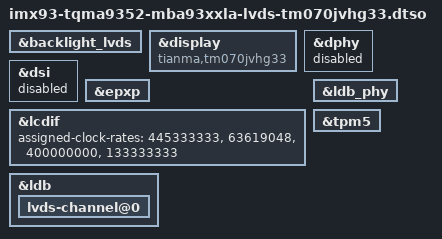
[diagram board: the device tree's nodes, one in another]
// SPDX-License-Identifier: (GPL-2.0-or-later OR MIT)
/*
 * Copyright (c) 2023-2024 TQ-Systems GmbH <linux@ew.tq-group.com>,
 * D-82229 Seefeld, Germany.
 * Author: Markus Niebel
 */

/dts-v1/;
/plugin/;

&backlight_lvds {
	status = "okay";
};

&display {
	compatible = "tianma,tm070jvhg33";
	status = "okay";
};

&dphy {
	status = "disabled";
};

&dsi {
	status = "disabled";
};

&epxp {
	status = "okay";
};

&lcdif {
	/* PLL -> pix_clk * 7 (LDB serial clk) */
	assigned-clock-rates = <445333333>, <63619048>, <400000000>, <133333333>;
	status = "okay";
};

&ldb {
	status = "okay";

	lvds-channel@0 {
		status = "okay";
	};
};

&ldb_phy {
	status = "okay";
};

&tpm5 {
	status = "okay";
};
